# WKUP_CTRL_MMR0_CFG0 register map
Vendor: Texas Instruments
Registers are 32-bit, read-write, reset 0x0 unless marked. A register's access mark holds for its fields unless they carry their own. Offsets are as the file gives them; [hi:lo] are bit positions; {n}, {i} and the like mark numbered series.

## WKUP_CTRL_MMR0_CFG0 (part 8 of 11)
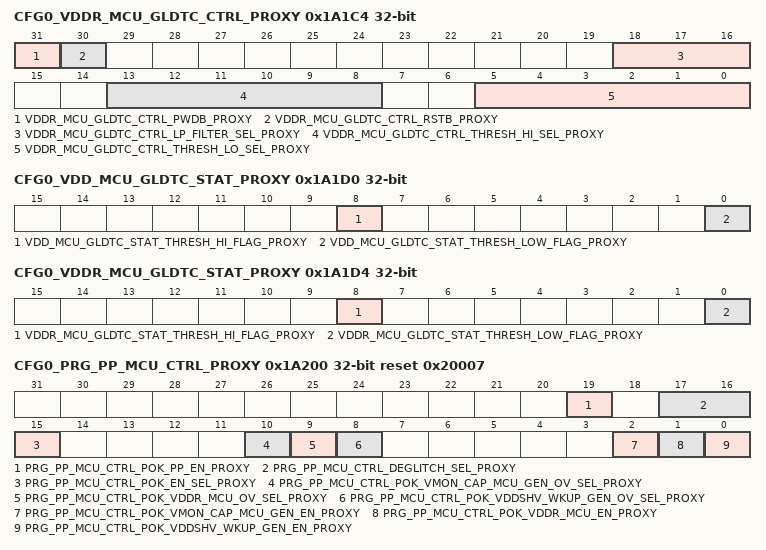
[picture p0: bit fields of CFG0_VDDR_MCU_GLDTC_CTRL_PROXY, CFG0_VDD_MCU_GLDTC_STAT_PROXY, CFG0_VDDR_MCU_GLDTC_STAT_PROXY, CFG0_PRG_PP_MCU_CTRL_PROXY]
0x1A1C4 CFG0_VDDR_MCU_GLDTC_CTRL_PROXY
  [31] VDDR_MCU_GLDTC_CTRL_PWDB_PROXY — Power down - active low. 0 - Disable all functions 1 - Enable glitch detectors
  [30] VDDR_MCU_GLDTC_CTRL_RSTB_PROXY — Reset - active low. To ensure proper operation, rstb must be not be de-asserted for at least 100 ns after power-up (pwdb de-asserted). Additionally, rstb must be toggled low at least 200 ns after any change in threshold or low-pass filter settings to prevent abnormal trigger events. 0 - Reset glitch detector flags 1 - Glitch detection flags are enabled
  [18:16] VDDR_MCU_GLDTC_CTRL_LP_FILTER_SEL_PROXY — Selects the glitch detect low-pass filter bandwidth Field values (others are reserved): 3'b000 - 150 kHz 3'b001 - 125 kHz 3'b010 - 100 kHz 3'b011 - 80 kHz 3'b100 - 60 kHz 3'b101 - 45 kHz 3'b110 - 30 kHz 3'b111 - 15 kHz
  [13:8] VDDR_MCU_GLDTC_CTRL_THRESH_HI_SEL_PROXY — Selects the high voltage glitch threshold as a percentage of the monitored voltage Field values (others are reserved): 6'b000000 - 93.5% of VDD 6'b000001 - 94.0% of VDD 6'b000010 - 94.5% of VDD 6'b000011 - 95.0% of VDD 6'b000100 - 95.5% of VDD 6'b000101 - 96.0% of VDD 6'b000110 - 96.5% of VDD 6'b000111 - 97.0% of VDD 6'b001000 - 97.5% of VDD 6'b001001 - 98.0% of VDD 6'b001010 - 98.5% of VDD 6'b001011 - 99.0% of VDD 6'b001100 - 99.5% of VDD 6'b001101 - 100.0% of VDD 6'b001110 - 100.5% of VDD 6'b001111 - 101.0% of VDD 6'b010000 - 101.5% of VDD 6'b010001 - 102.0% of VDD 6'b010010 - 102.5% of VDD 6'b010011 - 103.0% of VDD 6'b010100 - 103.5% of VDD 6'b010101 - 104.0% of VDD 6'b010110 - 104.5% of VDD 6'b010111 - 105.0% of VDD 6'b011000 - 105.5% of VDD 6'b011001 - 106.0% of VDD 6'b011010 - 106.5% of VDD 6'b011011 - 107.0% of VDD 6'b011100 - 107.5% of VDD 6'b011101 - 108.0% of VDD 6'b011110 - 108.5% of VDD 6'b011111 - 109.0% of VDD 6'b100000 - 109.5% of VDD 6'b100001 - 110.0% of VDD 6'b100010 - 111.0% of VDD 6'b100011 - 112.0% of VDD 6'b100100 - 113.0% of VDD 6'b100101 - 114.0% of VDD 6'b100110 - 115.0% of VDD 6'b100111 - 116.0% of VDD 6'b101000 - 117.0% of VDD 6'b101001 - 118.0% of VDD 6'b101010 - 119.0% of VDD 6'b101011 - 120.0% of VDD 6'b101100 - 121.0% of VDD 6'b101101 - 122.0% of VDD 6'b101110 - 123.0% of VDD 6'b101111 - 124.0% of VDD 6'b110000 - 125.0% of VDD 6'b110001 - 126.0% of VDD 6'b110010 - 127.0% of VDD 6'b110011 - 128.0% of VDD 6'b110100 - 129.0% of VDD 6'b110101 - 130.0% of VDD 6'b110110 - 131.0% of VDD 6'b110111 - 132.0% of VDD 6'b111000 - 133.0% of VDD 6'b111001 - 134.0% of VDD 6'b111010 - 135.0% of VDD 6'b111011 - 136.0% of VDD 6'b111100 - 137.0% of VDD 6'b111101 - 138.0% of VDD 6'b111110 - 139.0% of VDD 6'b111111 - 140.0% of VDD
  [5:0] VDDR_MCU_GLDTC_CTRL_THRESH_LO_SEL_PROXY — Selects the low voltage glitch threshold as a percentage of the monitored voltage Field values (others are reserved): 6'b000000 - 106.5% of VDD 6'b000001 - 106.0% of VDD 6'b000010 - 105.5% of VDD 6'b000011 - 105.0% of VDD 6'b000100 - 104.5% of VDD 6'b000101 - 104.0% of VDD 6'b000110 - 103.5% of VDD 6'b000111 - 103.0% of VDD 6'b001000 - 102.5% of VDD 6'b001001 - 102.0% of VDD 6'b001010 - 101.5% of VDD 6'b001011 - 101.0% of VDD 6'b001100 - 100.5% of VDD 6'b001101 - 100.0% of VDD 6'b001110 - 99.5% of VDD 6'b001111 - 99.0% of VDD 6'b010000 - 98.5% of VDD 6'b010001 - 98.0% of VDD 6'b010010 - 97.5% of VDD 6'b010011 - 97.0% of VDD 6'b010100 - 96.5% of VDD 6'b010101 - 96.0% of VDD 6'b010110 - 95.5% of VDD 6'b010111 - 95.0% of VDD 6'b011000 - 94.5% of VDD 6'b011001 - 94.0% of VDD 6'b011010 - 93.5% of VDD 6'b011011 - 93.0% of VDD 6'b011100 - 92.5% of VDD 6'b011101 - 92.0% of VDD 6'b011110 - 91.5% of VDD 6'b011111 - 91.0% of VDD 6'b100000 - 90.5% of VDD 6'b100001 - 90.0% of VDD 6'b100010 - 89.0% of VDD 6'b100011 - 88.0% of VDD 6'b100100 - 87.0% of VDD 6'b100101 - 86.0% of VDD 6'b100110 - 85.0% of VDD 6'b100111 - 84.0% of VDD 6'b101000 - 83.0% of VDD 6'b101001 - 82.0% of VDD 6'b101010 - 81.0% of VDD 6'b101011 - 80.0% of VDD 6'b101100 - 79.0% of VDD 6'b101101 - 78.0% of VDD 6'b101110 - 77.0% of VDD 6'b101111 - 76.0% of VDD 6'b110000 - 75.0% of VDD 6'b110001 - 74.0% of VDD 6'b110010 - 73.0% of VDD 6'b110011 - 72.0% of VDD 6'b110100 - 71.0% of VDD 6'b110101 - 70.0% of VDD 6'b110110 - 69.0% of VDD 6'b110111 - 68.0% of VDD 6'b111000 - 67.0% of VDD 6'b111001 - 66.0% of VDD 6'b111010 - 65.0% of VDD 6'b111011 - 64.0% of VDD 6'b111100 - 63.0% of VDD 6'b111101 - 62.0% of VDD 6'b111110 - 61.0% of VDD 6'b111111 - 60.0% of VDD
0x1A1D0 CFG0_VDD_MCU_GLDTC_STAT_PROXY ro
  [8] VDD_MCU_GLDTC_STAT_THRESH_HI_FLAG_PROXY — High voltage flag. This flag is cleared by clearing the VDD_MCU_GLDTC_CTRL_rstb bit. 0 - No high voltage detected 1 - Voltage above the high voltage threshold was detected.
  [0] VDD_MCU_GLDTC_STAT_THRESH_LOW_FLAG_PROXY — Low voltage flag. This flag is cleared by clearing the VDD_MCU_GLDTC_CTRL_rstb bit. 0 - No low voltage detected 1 - Voltage below the low voltage threshold was detected.
0x1A1D4 CFG0_VDDR_MCU_GLDTC_STAT_PROXY ro
  [8] VDDR_MCU_GLDTC_STAT_THRESH_HI_FLAG_PROXY — High voltage flag. This flag is cleared by clearing the VDDR_MCU_GLDTC_CTRL_rstb bit. 0 - No high voltage detected 1 - Voltage above the high voltage threshold was detected.
  [0] VDDR_MCU_GLDTC_STAT_THRESH_LOW_FLAG_PROXY — Low voltage flag. This flag is cleared by clearing the VDDR_MCU_GLDTC_CTRL_rstb bit. 0 - No low voltage detected 1 - Voltage below the low voltage threshold was detected.
0x1A200 CFG0_PRG_PP_MCU_CTRL_PROXY reset 0x20007
  [19] PRG_PP_MCU_CTRL_POK_PP_EN_PROXY — POK ping-pong enable. When set, enables automatic switching between undervoltage and overvoltage detection on VDDSHV_WKUP_GENERAL, VDDR_MCU and VMON_CAP_MCU_GENERAL POKs. This bit has no effect if the POK's ov_sel bit = 1. 0 - No pingpong operation. UV/OV operation selected by each POK ov_sel bit 1 - Pingpong operation enabled .
  [17:16] PRG_PP_MCU_CTRL_DEGLITCH_SEL_PROXY — Deglitch period for PRG_PP_MCU POKs Field values (others are reserved): 2'b00 - 5 us 2'b01 - 10 us 2'b10 - 15 us 2'b11 - 20 us
  [15] PRG_PP_MCU_CTRL_POK_EN_SEL_PROXY — Select POK enable source 0 - POK enables come from hardware tie-offs 1 - POK enables come from PRG_PP_MCU_CTRL register
  [10] PRG_PP_MCU_CTRL_POK_VMON_CAP_MCU_GEN_OV_SEL_PROXY — Force VMON_CAP_MCU_GENERAL POK overvoltage detection. If this bit is 0 and pok_pp_en bit is also 0 then only undervoltage detection is enabled. 0 - Undervoltage detection or UV/OV ping-pong operation 1- Overvoltage detection only
  [9] PRG_PP_MCU_CTRL_POK_VDDR_MCU_OV_SEL_PROXY — Force VDDR_MCU POK overvoltage detection. If this bit is 0 and pok_pp_en bit is also 0 then only undervoltage detection is enabled. 0 - Undervoltage detection or UV/OV ping-pong operation 1- Overvoltage detection only
  [8] PRG_PP_MCU_CTRL_POK_VDDSHV_WKUP_GEN_OV_SEL_PROXY — Force VDDSHV_WKUP_GENERAL POK overvoltage detection. If this bit is 0 and pok_pp_en bit is also 0 then only undervoltage detection is enabled. 0 - Undervoltage detection or UV/OV ping-pong operation 1- Overvoltage detection only
  [2] PRG_PP_MCU_CTRL_POK_VMON_CAP_MCU_GEN_EN_PROXY — Enable VMON_CAP_MCU_GENERAL POK detection 0 - POK detection disabled 1 - POK detection enabled
  [1] PRG_PP_MCU_CTRL_POK_VDDR_MCU_EN_PROXY — Enable VDDR_MCU POK detection 0 - POK detection disabled 1 - POK detection enabled
  [0] PRG_PP_MCU_CTRL_POK_VDDSHV_WKUP_GEN_EN_PROXY — Enable VDDSHV_WKUP_GENERAL POK detection 0 - POK detection disabled 1 - POK detection enabled
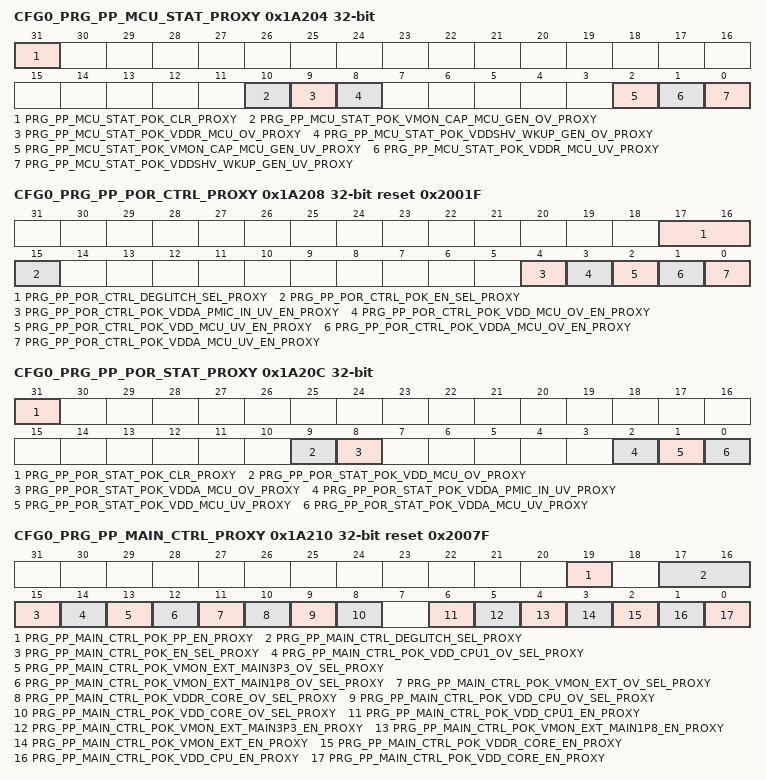
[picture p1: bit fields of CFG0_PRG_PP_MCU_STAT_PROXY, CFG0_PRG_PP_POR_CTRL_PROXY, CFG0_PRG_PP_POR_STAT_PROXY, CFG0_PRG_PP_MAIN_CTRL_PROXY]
0x1A204 CFG0_PRG_PP_MCU_STAT_PROXY access per field
  [31] PRG_PP_MCU_STAT_POK_CLR_PROXY rw — When set, resets pgood sticky bits for VDDSHV_WKUP_GENERAL, VDDR_MCU, and VMON_CAP_MCU_GENERAL voltage POK detection.
  [10] PRG_PP_MCU_STAT_POK_VMON_CAP_MCU_GEN_OV_PROXY ro — VMON_CAP_MCU_GENERAL overvoltage POK 0 - Voltage good 1 - Voltage above threshold
  [9] PRG_PP_MCU_STAT_POK_VDDR_MCU_OV_PROXY ro — VDDR_MCU overvoltage POK 0 - Voltage good 1 - Voltage above threshold
  [8] PRG_PP_MCU_STAT_POK_VDDSHV_WKUP_GEN_OV_PROXY ro — VDDSHV_WKUP_GENERAL overvoltage POK 0 - Voltage good 1 - Voltage above threshold
  [2] PRG_PP_MCU_STAT_POK_VMON_CAP_MCU_GEN_UV_PROXY ro — VMON_CAP_MCU_GENERAL undervoltage POK 0 - Voltage good 1 - Voltage below threshold
  [1] PRG_PP_MCU_STAT_POK_VDDR_MCU_UV_PROXY ro — VDDR_MCU undervoltage POK 0 - Voltage good 1 - Voltage below threshold
  [0] PRG_PP_MCU_STAT_POK_VDDSHV_WKUP_GEN_UV_PROXY ro — VDDSHV_WKUP_GENERAL undervoltage POK 0 - Voltage good 1 - Voltage below threshold
0x1A208 CFG0_PRG_PP_POR_CTRL_PROXY reset 0x2001F
  [17:16] PRG_PP_POR_CTRL_DEGLITCH_SEL_PROXY — Deglitch period for PRG_PP_POR POKs Field values (others are reserved): 2'b00 - 5 us 2'b01 - 10 us 2'b10 - 15 us 2'b11 - 20 us
  [15] PRG_PP_POR_CTRL_POK_EN_SEL_PROXY — Select POK enable source 0 - POK enables come from hardware tie-offs 1 - POK enables come from PRG_PP_POR_CTRL register
  [4] PRG_PP_POR_CTRL_POK_VDDA_PMIC_IN_UV_EN_PROXY — Enable VDDA_PMIC_IN undervoltage POK detection 0 - POK detection disabled 1 - POK detection enabled
  [3] PRG_PP_POR_CTRL_POK_VDD_MCU_OV_EN_PROXY — Enable VDD_MCU overvoltage POK detection 0 - POK detection disabled 1 - POK detection enabled
  [2] PRG_PP_POR_CTRL_POK_VDD_MCU_UV_EN_PROXY — Enable VDD_MCU undervoltage POK detection 0 - POK detection disabled 1 - POK detection enabled
  [1] PRG_PP_POR_CTRL_POK_VDDA_MCU_OV_EN_PROXY — Enable 1.8V VDDA_MCU overvoltage POK detection 0 - POK detection disabled 1 - POK detection enabled
  [0] PRG_PP_POR_CTRL_POK_VDDA_MCU_UV_EN_PROXY — Enable 1.8V VDDA_MCU undervoltage POK detection 0 - POK detection disabled 1 - POK detection enabled
0x1A20C CFG0_PRG_PP_POR_STAT_PROXY access per field
  [31] PRG_PP_POR_STAT_POK_CLR_PROXY rw — When set, resets pgood sticky bits for VDDA_MCU, VDD_MCU, and VDDA_PMIC_IN voltage POK detection.
  [9] PRG_PP_POR_STAT_POK_VDD_MCU_OV_PROXY ro — VDD_MCU overvoltage POK detection 0 - Voltage good 1 - Voltage above threshold
  [8] PRG_PP_POR_STAT_POK_VDDA_MCU_OV_PROXY ro — 1.8V VDDA_MCU overvoltage POK detection 0 - Voltage good 1 - Voltage above threshold
  [2] PRG_PP_POR_STAT_POK_VDDA_PMIC_IN_UV_PROXY ro — VDDA_PMIC_IN undervoltage POK detection 0 - Voltage good 1 - Voltage below threshold
  [1] PRG_PP_POR_STAT_POK_VDD_MCU_UV_PROXY ro — VDD_MCU undervoltage POK detection 0 - Voltage good 1 - Voltage below threshold
  [0] PRG_PP_POR_STAT_POK_VDDA_MCU_UV_PROXY ro — 1.8V VDDA_MCU undervoltage POK detection 0 - Voltage good 1 - Voltage below threshold
0x1A210 CFG0_PRG_PP_MAIN_CTRL_PROXY reset 0x2007F
  [19] PRG_PP_MAIN_CTRL_POK_PP_EN_PROXY — POK ping-pong enable. When set, enables automatic switching between undervoltage and overvoltage detection on VDD_CORE, VDD_CPU, VDDR_CORE, VMON_EXT, VMON_EXT_MAIN1P8 and VMON_EXT_MAIN3P3. This bit has no effect if the POK's ov_sel bit = 1. 0 - No pingpong operation. UV/OV operation selected by each POK ov_sel bit 1 - Pingpong operation enabled .
  [17:16] PRG_PP_MAIN_CTRL_DEGLITCH_SEL_PROXY — Deglitch period for PRG_PP_MAIN POKs Field values (others are reserved): 2'b00 - 5 us 2'b01 - 10 us 2'b10 - 15 us 2'b11 - 20 us
  [15] PRG_PP_MAIN_CTRL_POK_EN_SEL_PROXY — Select POK enable source 0 - POK enables come from hardware tie-offs 1 - POK enables come from PRG_PP_MAIN_CTRL register
  [14] PRG_PP_MAIN_CTRL_POK_VDD_CPU1_OV_SEL_PROXY — Force VDD_CPU1 POK overvoltage detection. If this bit is 0 and pok_pp_en bit is also 0 then only undervoltage detection is enabled. 0 - Undervoltage detection or UV/OV ping-pong operation 1- Overvoltage detection only
  [13] PRG_PP_MAIN_CTRL_POK_VMON_EXT_MAIN3P3_OV_SEL_PROXY — Force VMON_EXT_MAIN 3.3V POK overvoltage detection. If this bit is 0 and pok_pp_en bit is also 0 then only undervoltage detection is enabled. 0 - Undervoltage detection or UV/OV ping-pong operation 1- Overvoltage detection only
  [12] PRG_PP_MAIN_CTRL_POK_VMON_EXT_MAIN1P8_OV_SEL_PROXY — Force VMON_EXT_MAIN 1.8V POK overvoltage detection. If this bit is 0 and pok_pp_en bit is also 0 then only undervoltage detection is enabled. 0 - Undervoltage detection or UV/OV ping-pong operation 1- Overvoltage detection only
  [11] PRG_PP_MAIN_CTRL_POK_VMON_EXT_OV_SEL_PROXY — Force VMON_EXT POK overvoltage detection. If this bit is 0 and pok_pp_en bit is also 0 then only undervoltage detection is enabled. 0 - Undervoltage detection or UV/OV ping-pong operation 1- Overvoltage detection only
  [10] PRG_PP_MAIN_CTRL_POK_VDDR_CORE_OV_SEL_PROXY — Force VDDR_CORE POK overvoltage detection. If this bit is 0 and pok_pp_en bit is also 0 then only undervoltage detection is enabled. 0 - Undervoltage detection or UV/OV ping-pong operation 1- Overvoltage detection only
  [9] PRG_PP_MAIN_CTRL_POK_VDD_CPU_OV_SEL_PROXY — Force VDD_CPU POK overvoltage detection. If this bit is 0 and pok_pp_en bit is also 0 then only undervoltage detection is enabled. 0 - Undervoltage detection or UV/OV ping-pong operation 1- Overvoltage detection only
  [8] PRG_PP_MAIN_CTRL_POK_VDD_CORE_OV_SEL_PROXY — Force VDD_CORE POK overvoltage detection. If this bit is 0 and pok_pp_en bit is also 0 then only undervoltage detection is enabled. 0 - Undervoltage detection or UV/OV ping-pong operation 1- Overvoltage detection only
  [6] PRG_PP_MAIN_CTRL_POK_VDD_CPU1_EN_PROXY — Enable VDD_CPU1 POK detection 0 - POK detection disabled 1 - POK detection enabled
  [5] PRG_PP_MAIN_CTRL_POK_VMON_EXT_MAIN3P3_EN_PROXY — Enable VMON_EXT_MAIN 3.3V POK detection 0 - POK detection disabled 1 - POK detection enabled
  [4] PRG_PP_MAIN_CTRL_POK_VMON_EXT_MAIN1P8_EN_PROXY — Enable VMON_EXT_MAIN 1.8V POK detection 0 - POK detection disabled 1 - POK detection enabled
  [3] PRG_PP_MAIN_CTRL_POK_VMON_EXT_EN_PROXY — Enable VMON_EXT POK detection 0 - POK detection disabled 1 - POK detection enabled
  [2] PRG_PP_MAIN_CTRL_POK_VDDR_CORE_EN_PROXY — Enable VDDR_CORE POK detection 0 - POK detection disabled 1 - POK detection enabled
  [1] PRG_PP_MAIN_CTRL_POK_VDD_CPU_EN_PROXY — Enable VDD_CPU POK detection 0 - POK detection disabled 1 - POK detection enabled
  [0] PRG_PP_MAIN_CTRL_POK_VDD_CORE_EN_PROXY — Enable VDD_CORE POK detection 0 - POK detection disabled 1 - POK detection enabled
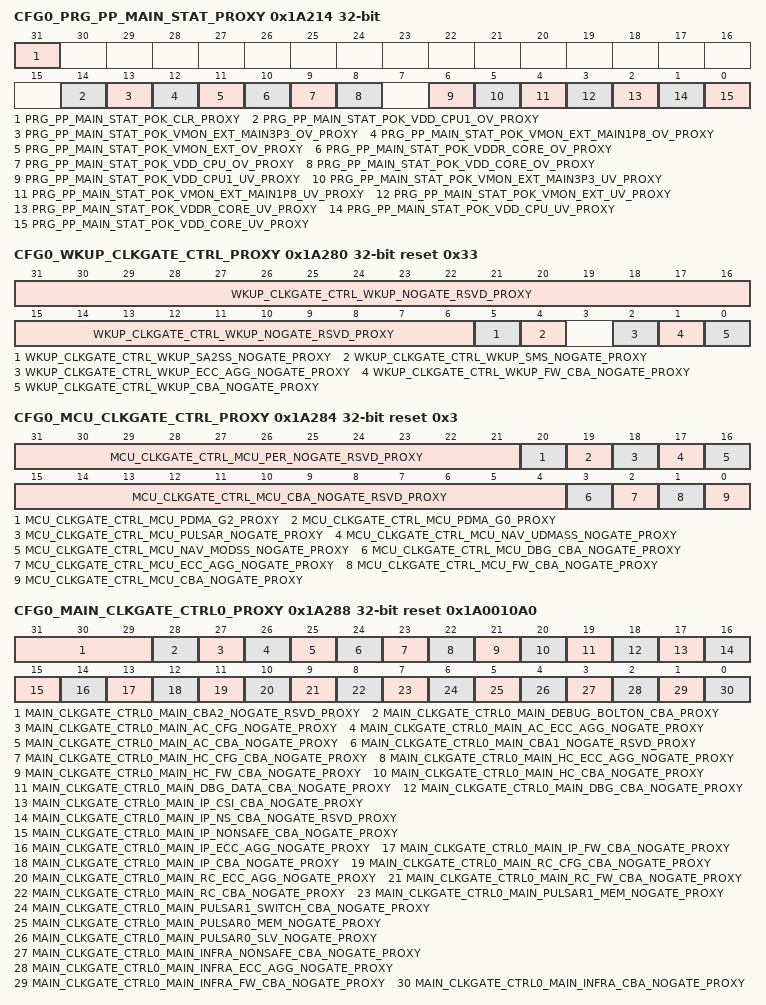
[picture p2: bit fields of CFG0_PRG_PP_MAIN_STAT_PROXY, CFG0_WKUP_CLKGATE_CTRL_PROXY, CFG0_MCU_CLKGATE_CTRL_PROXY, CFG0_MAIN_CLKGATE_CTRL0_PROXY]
0x1A214 CFG0_PRG_PP_MAIN_STAT_PROXY access per field
  [31] PRG_PP_MAIN_STAT_POK_CLR_PROXY rw — When set, resets pgood sticky bits for VDD_CORE, VDD_CPU, VDDR_CORE, VMON_EXT, VMON_EXT_MAIN1P8, and VMON_EXT_MAIN3P3 voltage POK detection.
  [14] PRG_PP_MAIN_STAT_POK_VDD_CPU1_OV_PROXY ro — VDD_CPU1 overvoltage POK 0 - Voltage good 1 - Voltage above threshold
  [13] PRG_PP_MAIN_STAT_POK_VMON_EXT_MAIN3P3_OV_PROXY ro — VMON_EXT_MAIN 3.3V overvoltage POK 0 - Voltage good 1 - Voltage above threshold
  [12] PRG_PP_MAIN_STAT_POK_VMON_EXT_MAIN1P8_OV_PROXY ro — VMON_EXT_MAIN 1.8V overvoltage POK 0 - Voltage good 1 - Voltage above threshold
  [11] PRG_PP_MAIN_STAT_POK_VMON_EXT_OV_PROXY ro — VMON_EXT overvoltage POK 0 - Voltage good 1 - Voltage above threshold
  [10] PRG_PP_MAIN_STAT_POK_VDDR_CORE_OV_PROXY ro — VDDR_CORE overvoltage POK 0 - Voltage good 1 - Voltage above threshold
  [9] PRG_PP_MAIN_STAT_POK_VDD_CPU_OV_PROXY ro — VDD_CPU overvoltage POK 0 - Voltage good 1 - Voltage above threshold
  [8] PRG_PP_MAIN_STAT_POK_VDD_CORE_OV_PROXY ro — VDD_CORE overvoltage POK 0 - Voltage good 1 - Voltage above threshold
  [6] PRG_PP_MAIN_STAT_POK_VDD_CPU1_UV_PROXY ro — VDD_CPU1 undervoltage POK 0 - Voltage good 1 - Voltage below threshold
  [5] PRG_PP_MAIN_STAT_POK_VMON_EXT_MAIN3P3_UV_PROXY ro — VMON_EXT_MAIN 3.3V undervoltage POK 0 - Voltage good 1 - Voltage below threshold
  [4] PRG_PP_MAIN_STAT_POK_VMON_EXT_MAIN1P8_UV_PROXY ro — VMON_EXT_MAIN 1.8V undervoltage POK 0 - Voltage good 1 - Voltage below threshold
  [3] PRG_PP_MAIN_STAT_POK_VMON_EXT_UV_PROXY ro — VMON_EXT undervoltage POK 0 - Voltage good 1 - Voltage below threshold
  [2] PRG_PP_MAIN_STAT_POK_VDDR_CORE_UV_PROXY ro — VDDR_CORE undervoltage POK 0 - Voltage good 1 - Voltage below threshold
  [1] PRG_PP_MAIN_STAT_POK_VDD_CPU_UV_PROXY ro — VDD_CPU undervoltage POK 0 - Voltage good 1 - Voltage below threshold
  [0] PRG_PP_MAIN_STAT_POK_VDD_CORE_UV_PROXY ro — VDD_CORE undervoltage POK 0 - Voltage good 1 - Voltage below threshold
0x1A280 CFG0_WKUP_CLKGATE_CTRL_PROXY reset 0x33
  [31:6] WKUP_CLKGATE_CTRL_WKUP_NOGATE_RSVD_PROXY — WKUP reserved clock gate disable. These bits should remain unchanged (written only with their default value) to maintain compatibility with future devices. 0 - Clocks are gated on idle for power savings 1 - Clocks are not gated on idle, power saving disabled
  [5] WKUP_CLKGATE_CTRL_WKUP_SA2SS_NOGATE_PROXY — WKUP SA2SS clock gate disable 0 - Clocks are gated on idle for power savings 1 - Clocks are not gated on idle, power saving disabled
  [4] WKUP_CLKGATE_CTRL_WKUP_SMS_NOGATE_PROXY — WKUP SMS clock gate disable 0 - Clocks are gated on idle for power savings 1 - Clocks are not gated on idle, power saving disabled
  [2] WKUP_CLKGATE_CTRL_WKUP_ECC_AGG_NOGATE_PROXY — WKUP ECC Aggregator clock gate disable 0 - Clocks are gated on idle for power savings 1 - Clocks are not gated on idle, power saving disabled
  [1] WKUP_CLKGATE_CTRL_WKUP_FW_CBA_NOGATE_PROXY — WKUP domain Firewall bus (wkup_fw_cbass) clock gate disable 0 - Clocks are gated on idle for power savings 1 - Clocks are not gated on idle, power saving disabled
  [0] WKUP_CLKGATE_CTRL_WKUP_CBA_NOGATE_PROXY — WKUP domain Data bus (wkup_cbass) clock gate disable 0 - Clocks are gated on idle for power savings 1 - Clocks are not gated on idle, power saving disabled
0x1A284 CFG0_MCU_CLKGATE_CTRL_PROXY reset 0x3
  [31:21] MCU_CLKGATE_CTRL_MCU_PER_NOGATE_RSVD_PROXY — MCU reserved clock gate disable. These bits should remain unchanged (written only with their default value) to maintain compatibility with future devices. 0 - Clocks are gated on idle for power savings 1 - Clocks are not gated on idle, power saving disabled
  [20] MCU_CLKGATE_CTRL_MCU_PDMA_G2_PROXY — MCU domain MCAN1/USART0 PDMA clock gate disable. 0 - Clocks are gated on idle for power savings 1 - Clocks are not gated on idle, power saving disabled
  [19] MCU_CLKGATE_CTRL_MCU_PDMA_G0_PROXY — MCU domain MCAN0/SPI0 PDMA clock gate disable. 0 - Clocks are gated on idle for power savings 1 - Clocks are not gated on idle, power saving disabled
  [18] MCU_CLKGATE_CTRL_MCU_PULSAR_NOGATE_PROXY — MCU domain Pulsar clock gate disable. 0 - Clocks are gated on idle for power savings 1 - Clocks are not gated on idle, power saving disabled
  [17] MCU_CLKGATE_CTRL_MCU_NAV_UDMASS_NOGATE_PROXY — MCU NavSS UDMA interface clock gate disable. 0 - Clocks are gated on idle for power savings 1 - Clocks are not gated on idle, power saving disabled
  [16] MCU_CLKGATE_CTRL_MCU_NAV_MODSS_NOGATE_PROXY — MCU NavSS MODSS interface clock gate disable. 0 - Clocks are gated on idle for power savings 1 - Clocks are not gated on idle, power saving disabled
  [15:4] MCU_CLKGATE_CTRL_MCU_CBA_NOGATE_RSVD_PROXY — MCU reserved clock gate disable. These bits should remain unchanged (written only with their default value) to maintain compatibility with future devices. 0 - Clocks are gated on idle for power savings 1 - Clocks are not gated on idle, power saving disabled
  [3] MCU_CLKGATE_CTRL_MCU_DBG_CBA_NOGATE_PROXY — MCU domain Debug bus (mcu_dbg_cbass) clock gate disable. 0 - Clocks are gated on idle for power savings 1 - Clocks are not gated on idle, power saving disabled
  [2] MCU_CLKGATE_CTRL_MCU_ECC_AGG_NOGATE_PROXY — MCU ECC Aggregator clock gate disable 0 - Clocks are gated on idle for power savings 1 - Clocks are not gated on idle, power saving disabled
  [1] MCU_CLKGATE_CTRL_MCU_FW_CBA_NOGATE_PROXY — MCU domain Firewall bus (mcu_fw_cbass) clock gate disable. 0 - Clocks are gated on idle for power savings 1 - Clocks are not gated on idle, power saving disabled
  [0] MCU_CLKGATE_CTRL_MCU_CBA_NOGATE_PROXY — MCU domain Data bus (mcu_cbass) clock gate disable. 0 - Clocks are gated on idle for power savings 1 - Clocks are not gated on idle, power saving disabled
0x1A288 CFG0_MAIN_CLKGATE_CTRL0_PROXY reset 0x1A0010A0
  [31:29] MAIN_CLKGATE_CTRL0_MAIN_CBA2_NOGATE_RSVD_PROXY — MAIN CBA reserved clock gate disable. These bits should remain unchanged (written only with their default value) to maintain compatibility with future devices. 0 - Clocks are gated on idle for power savings 1 - Clocks are not gated on idle, power saving disabled
  [28] MAIN_CLKGATE_CTRL0_MAIN_DEBUG_BOLTON_CBA_PROXY — MAIN domain debug bolton bus (debug_bolton_cbass) clock gate disable. 0 - Clocks are gated on idle for power savings 1 - Clocks are not gated on idle, power saving disabled
  [27] MAIN_CLKGATE_CTRL0_MAIN_AC_CFG_NOGATE_PROXY — MAIN domain AC Configuration bus (ac_cfg_fw_cbass) clock gate disable. 0 - Clocks are gated on idle for power savings 1 - Clocks are not gated on idle, power saving disabled
  [26] MAIN_CLKGATE_CTRL0_MAIN_AC_ECC_AGG_NOGATE_PROXY — MAIN domain AC ECC aggregator bus (ac_pipe_ecc_aggr) clock gate disable. 0 - Clocks are gated on idle for power savings 1 - Clocks are not gated on idle, power saving disabled
  [25] MAIN_CLKGATE_CTRL0_MAIN_AC_CBA_NOGATE_PROXY — MAIN domain AC Firewall bus (ac_pipe_cbass_main_fw_cbass_0) clock gate disable. 0 - Clocks are gated on idle for power savings 1 - Clocks are not gated on idle, power saving disabled
  [24] MAIN_CLKGATE_CTRL0_MAIN_CBA1_NOGATE_RSVD_PROXY — MAIN CBA reserved clock gate disable. These bits should remain unchanged (written only with their default value) to maintain compatibility with future devices. 0 - Clocks are gated on idle for power savings 1 - Clocks are not gated on idle, power saving disabled
  [23] MAIN_CLKGATE_CTRL0_MAIN_HC_CFG_CBA_NOGATE_PROXY — MAIN domain HC Configuration bus (hc_cfg_cbass_0) clock gate disable. 0 - Clocks are gated on idle for power savings 1 - Clocks are not gated on idle, power saving disabled
  [22] MAIN_CLKGATE_CTRL0_MAIN_HC_ECC_AGG_NOGATE_PROXY — MAIN domain HC ECC aggregator (nogate) clock gate disable. 0 - Clocks are gated on idle for power savings 1 - Clocks are not gated on idle, power saving disabled
  [21] MAIN_CLKGATE_CTRL0_MAIN_HC_FW_CBA_NOGATE_PROXY — MAIN domain HC Firewall bus (main_hc2_fw_cbass_0) clock gate disable. 0 - Clocks are gated on idle for power savings 1 - Clocks are not gated on idle, power saving disabled
  [20] MAIN_CLKGATE_CTRL0_MAIN_HC_CBA_NOGATE_PROXY — MAIN domain HC Data bus (hc2_cbass_0) clock gate disable. 0 - Clocks are gated on idle for power savings 1 - Clocks are not gated on idle, power saving disabled
  [19] MAIN_CLKGATE_CTRL0_MAIN_DBG_DATA_CBA_NOGATE_PROXY — MAIN domain Debug Data bus (debug_cbass) clock gate disable. 0 - Clocks are gated on idle for power savings 1 - Clocks are not gated on idle, power saving disabled
  [18] MAIN_CLKGATE_CTRL0_MAIN_DBG_CBA_NOGATE_PROXY — MAIN domain Debug bus (debug_cbass_wrap_main_0) clock gate disable. 0 - Clocks are gated on idle for power savings 1 - Clocks are not gated on idle, power saving disabled
  [17] MAIN_CLKGATE_CTRL0_MAIN_IP_CSI_CBA_NOGATE_PROXY — MAIN domain CSI bus (csi_cbass_0) clock gate disable. 0 - Clocks are gated on idle for power savings 1 - Clocks are not gated on idle, power saving disabled
  [16] MAIN_CLKGATE_CTRL0_MAIN_IP_NS_CBA_NOGATE_RSVD_PROXY — MAIN nonsafety CBA reserved clock gate disable. These bits should remain unchanged (written only with their default value) to maintain compatibility with future devices. 0 - Clocks are gated on idle for power savings 1 - Clocks are not gated on idle, power saving disabled
  [15] MAIN_CLKGATE_CTRL0_MAIN_IP_NONSAFE_CBA_NOGATE_PROXY — MAIN domain Interface Peripheral nonsafety IP bus (ipphy_cbass_0) clock gate disable. 0 - Clocks are gated on idle for power savings 1 - Clocks are not gated on idle, power saving disabled
  [14] MAIN_CLKGATE_CTRL0_MAIN_IP_ECC_AGG_NOGATE_PROXY — MAIN domain Interface Peripheral ECC aggregator (main_spi0_g0_main_0_ecc_aggr_main_0) clock gate disable. 0 - Clocks are gated on idle for power savings 1 - Clocks are not gated on idle, power saving disabled
  [13] MAIN_CLKGATE_CTRL0_MAIN_IP_FW_CBA_NOGATE_PROXY — MAIN domain Interface Peripheral Firewall bus (ipphy_cbass_main_fw_cbass) clock gate disable. 0 - Clocks are gated on idle for power savings 1 - Clocks are not gated on idle, power saving disabled
  [12] MAIN_CLKGATE_CTRL0_MAIN_IP_CBA_NOGATE_PROXY — MAIN domain Interface Peripheral bus (ipphy_safe_cbass_0) clock gate disable. 0 - Clocks are gated on idle for power savings 1 - Clocks are not gated on idle, power saving disabled
  [11] MAIN_CLKGATE_CTRL0_MAIN_RC_CFG_CBA_NOGATE_PROXY — MAIN domain RC Configuration bus (rc_cfg_cbass_0) clock gate disable. 0 - Clocks are gated on idle for power savings 1 - Clocks are not gated on idle, power saving disabled
  [10] MAIN_CLKGATE_CTRL0_MAIN_RC_ECC_AGG_NOGATE_PROXY — MAIN domain RC ECC aggregator (main_rc_ecc_aggr_main_0) clock gate disable. 0 - Clocks are gated on idle for power savings 1 - Clocks are not gated on idle, power saving disabled
  [9] MAIN_CLKGATE_CTRL0_MAIN_RC_FW_CBA_NOGATE_PROXY — MAIN domain RC Firewall bus (rc_cbass_main_fw_cbass) clock gate disable. 0 - Clocks are gated on idle for power savings 1 - Clocks are not gated on idle, power saving disabled
  [8] MAIN_CLKGATE_CTRL0_MAIN_RC_CBA_NOGATE_PROXY — MAIN domain RC Data bus (rc_cbass_0) clock gate disable. 0 - Clocks are gated on idle for power savings 1 - Clocks are not gated on idle, power saving disabled
  [7] MAIN_CLKGATE_CTRL0_MAIN_PULSAR1_MEM_NOGATE_PROXY — MAIN domain Pulsar 1 memory bus (pulsar1_mem_cbass) clock gate disable. 0 - Clocks are gated on idle for power savings 1 - Clocks are not gated on idle, power saving disabled
  [6] MAIN_CLKGATE_CTRL0_MAIN_PULSAR1_SWITCH_CBA_NOGATE_PROXY — MAIN domain Pulsar 1 peripheral switch bus (pulsar1_periph_switch_cbass) clock gate disable. 0 - Clocks are gated on idle for power savings 1 - Clocks are not gated on idle, power saving disabled
  [5] MAIN_CLKGATE_CTRL0_MAIN_PULSAR0_MEM_NOGATE_PROXY — MAIN domain Pulsar 0 memory bus (pulsar0_mem_cbass) clock gate disable. 0 - Clocks are gated on idle for power savings 1 - Clocks are not gated on idle, power saving disabled
  [4] MAIN_CLKGATE_CTRL0_MAIN_PULSAR0_SLV_NOGATE_PROXY — MAIN domain Pulsar slave bus (pulsar0_slv_cbass) clock gate disable. 0 - Clocks are gated on idle for power savings 1 - Clocks are not gated on idle, power saving disabled
  [3] MAIN_CLKGATE_CTRL0_MAIN_INFRA_NONSAFE_CBA_NOGATE_PROXY — MAIN domain Infrastructure non-safety IP bus (main_infra_non_safe_cbass) clock gate disable. 0 - Clocks are gated on idle for power savings 1 - Clocks are not gated on idle, power saving disabled
  [2] MAIN_CLKGATE_CTRL0_MAIN_INFRA_ECC_AGG_NOGATE_PROXY — MAIN domain Infrastructure ECC aggregator (main_infra_ecc_aggr) clock gate disable. 0 - Clocks are gated on idle for power savings 1 - Clocks are not gated on idle, power saving disabled
  [1] MAIN_CLKGATE_CTRL0_MAIN_INFRA_FW_CBA_NOGATE_PROXY — MAIN domain Infrastructure Firewall bus (main_infra_fw_cbass) clock gate disable. 0 - Clocks are gated on idle for power savings 1 - Clocks are not gated on idle, power saving disabled
  [0] MAIN_CLKGATE_CTRL0_MAIN_INFRA_CBA_NOGATE_PROXY — MAIN domain Infrastructure bus (main_infra_cbass) clock gate disable. 0 - Clocks are gated on idle for power savings 1 - Clocks are not gated on idle, power saving disabled
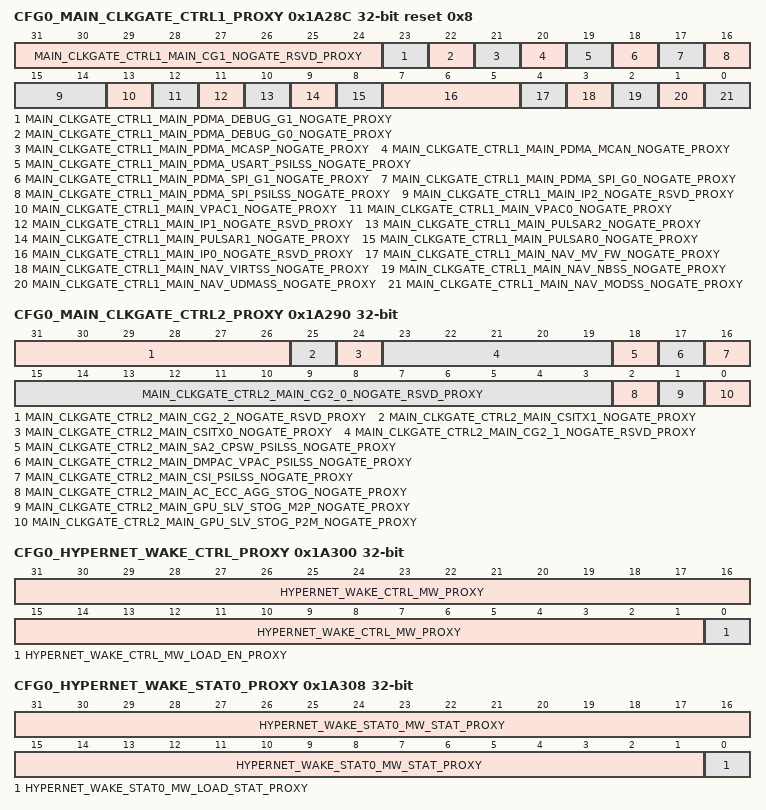
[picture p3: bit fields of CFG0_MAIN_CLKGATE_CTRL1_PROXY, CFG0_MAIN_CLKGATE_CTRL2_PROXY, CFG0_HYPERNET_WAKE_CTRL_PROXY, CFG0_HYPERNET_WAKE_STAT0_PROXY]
0x1A28C CFG0_MAIN_CLKGATE_CTRL1_PROXY reset 0x8
  [31:24] MAIN_CLKGATE_CTRL1_MAIN_CG1_NOGATE_RSVD_PROXY — MAIN PDMA clock gate disable. These bits should remain unchanged (written only with their default value) to maintain compatibility with future devices. 0 - Clocks are gated on idle for power savings 1 - Clocks are not gated on idle, power saving disabled
  [23] MAIN_CLKGATE_CTRL1_MAIN_PDMA_DEBUG_G1_NOGATE_PROXY — MAIN domain PDMA Debug_G1 clock gate disable. 0 - Clocks are gated on idle for power savings 1 - Clocks are not gated on idle, power saving disabled
  [22] MAIN_CLKGATE_CTRL1_MAIN_PDMA_DEBUG_G0_NOGATE_PROXY — MAIN domain PDMA Debug_G0 clock gate disable. 0 - Clocks are gated on idle for power savings 1 - Clocks are not gated on idle, power saving disabled
  [21] MAIN_CLKGATE_CTRL1_MAIN_PDMA_MCASP_NOGATE_PROXY — MAIN domain PDMA MCASP clock gate disable. 0 - Clocks are gated on idle for power savings 1 - Clocks are not gated on idle, power saving disabled
  [20] MAIN_CLKGATE_CTRL1_MAIN_PDMA_MCAN_NOGATE_PROXY — MAIN domain PDMA MCAN clock gate disable. 0 - Clocks are gated on idle for power savings 1 - Clocks are not gated on idle, power saving disabled
  [19] MAIN_CLKGATE_CTRL1_MAIN_PDMA_USART_PSILSS_NOGATE_PROXY — MAIN domain PDMA USART PSILSS clock gate disable. 0 - Clocks are gated on idle for power savings 1 - Clocks are not gated on idle, power saving disabled
  [18] MAIN_CLKGATE_CTRL1_MAIN_PDMA_SPI_G1_NOGATE_PROXY — MAIN domain PDMA SPI_G1 clock gate disable. 0 - Clocks are gated on idle for power savings 1 - Clocks are not gated on idle, power saving disabled
  [17] MAIN_CLKGATE_CTRL1_MAIN_PDMA_SPI_G0_NOGATE_PROXY — MAIN domain PDMA SPI_G0 clock gate disable. 0 - Clocks are gated on idle for power savings 1 - Clocks are not gated on idle, power saving disabled
  [16] MAIN_CLKGATE_CTRL1_MAIN_PDMA_SPI_PSILSS_NOGATE_PROXY — MAIN domain PDMA SPI PSILSS clock gate disable. 0 - Clocks are gated on idle for power savings 1 - Clocks are not gated on idle, power saving disabled
  [15:14] MAIN_CLKGATE_CTRL1_MAIN_IP2_NOGATE_RSVD_PROXY — MAIN IP reserved clock gate disable. These bits should remain unchanged (written only with their default value) to maintain compatibility with future devices. 0 - Clocks are gated on idle for power savings 1 - Clocks are not gated on idle, power saving disabled
  [13] MAIN_CLKGATE_CTRL1_MAIN_VPAC1_NOGATE_PROXY — MAIN domain VPAC 1 clock gate disable. 0 - Clocks are gated on idle for power savings 1 - Clocks are not gated on idle, power saving disabled
  [12] MAIN_CLKGATE_CTRL1_MAIN_VPAC0_NOGATE_PROXY — MAIN domain VPAC 0 clock gate disable. 0 - Clocks are gated on idle for power savings 1 - Clocks are not gated on idle, power saving disabled
  [11] MAIN_CLKGATE_CTRL1_MAIN_IP1_NOGATE_RSVD_PROXY — MAIN IP reserved clock gate disable. These bits should remain unchanged (written only with their default value) to maintain compatibility with future devices. 0 - Clocks are gated on idle for power savings 1 - Clocks are not gated on idle, power saving disabled
  [10] MAIN_CLKGATE_CTRL1_MAIN_PULSAR2_NOGATE_PROXY — MAIN domain Pulsar 2 clock gate disable. 0 - Clocks are gated on idle for power savings 1 - Clocks are not gated on idle, power saving disabled
  [9] MAIN_CLKGATE_CTRL1_MAIN_PULSAR1_NOGATE_PROXY — MAIN domain Pulsar 1 clock gate disable. 0 - Clocks are gated on idle for power savings 1 - Clocks are not gated on idle, power saving disabled
  [8] MAIN_CLKGATE_CTRL1_MAIN_PULSAR0_NOGATE_PROXY — MAIN domain Pulsar 0 clock gate disable. 0 - Clocks are gated on idle for power savings 1 - Clocks are not gated on idle, power saving disabled
  [7:5] MAIN_CLKGATE_CTRL1_MAIN_IP0_NOGATE_RSVD_PROXY — MAIN IP reserved clock gate disable. These bits should remain unchanged (written only with their default value) to maintain compatibility with future devices. 0 - Clocks are gated on idle for power savings 1 - Clocks are not gated on idle, power saving disabled
  [4] MAIN_CLKGATE_CTRL1_MAIN_NAV_MV_FW_NOGATE_PROXY — MAIN NavSS Mod/Virt Firewall interface clock gate disable. 0 - Clocks are gated on idle for power savings 1 - Clocks are not gated on idle, power saving disabled
  [3] MAIN_CLKGATE_CTRL1_MAIN_NAV_VIRTSS_NOGATE_PROXY — MAIN NavSS VIRTSS interface clock gate disable. 0 - Clocks are gated on idle for power savings 1 - Clocks are not gated on idle, power saving disabled
  [2] MAIN_CLKGATE_CTRL1_MAIN_NAV_NBSS_NOGATE_PROXY — MAIN NavSS NB interface clock gate disable. 0 - Clocks are gated on idle for power savings 1 - Clocks are not gated on idle, power saving disabled
  [1] MAIN_CLKGATE_CTRL1_MAIN_NAV_UDMASS_NOGATE_PROXY — Main NavSS UDMA interface clock gate disable. 0 - Clocks are gated on idle for power savings 1 - Clocks are not gated on idle, power saving disabled
  [0] MAIN_CLKGATE_CTRL1_MAIN_NAV_MODSS_NOGATE_PROXY — MAIN NavSS MODSS interface clock gate disable. 0 - Clocks are gated on idle for power savings 1 - Clocks are not gated on idle, power saving disabled
0x1A290 CFG0_MAIN_CLKGATE_CTRL2_PROXY
  [31:26] MAIN_CLKGATE_CTRL2_MAIN_CG2_2_NOGATE_RSVD_PROXY — MAIN domain spare clock gate disable. These bits should remain unchanged (written only with their default value) to maintain compatibility with future devices. 0 - Clocks are gated on idle for power savings 1 - Clocks are not gated on idle, power saving disabled
  [25] MAIN_CLKGATE_CTRL2_MAIN_CSITX1_NOGATE_PROXY — MAIN domain CSI_TX1 clock gate disable. 0 - Clocks are gated on idle for power savings 1 - Clocks are not gated on idle, power saving disabled
  [24] MAIN_CLKGATE_CTRL2_MAIN_CSITX0_NOGATE_PROXY — MAIN domain CSI_TX0 clock gate disable. 0 - Clocks are gated on idle for power savings 1 - Clocks are not gated on idle, power saving disabled
  [23:19] MAIN_CLKGATE_CTRL2_MAIN_CG2_1_NOGATE_RSVD_PROXY — MAIN domain spare clock gate disable. These bits should remain unchanged (written only with their default value) to maintain compatibility with future devices. 0 - Clocks are gated on idle for power savings 1 - Clocks are not gated on idle, power saving disabled
  [18] MAIN_CLKGATE_CTRL2_MAIN_SA2_CPSW_PSILSS_NOGATE_PROXY — MAIN domain SA2_UL/SPCW PSILSS clock gate disable. 0 - Clocks are gated on idle for power savings 1 - Clocks are not gated on idle, power saving disabled
  [17] MAIN_CLKGATE_CTRL2_MAIN_DMPAC_VPAC_PSILSS_NOGATE_PROXY — MAIN domain DMPAC/VPAC PSILSS clock gate disable. 0 - Clocks are gated on idle for power savings 1 - Clocks are not gated on idle, power saving disabled
  [16] MAIN_CLKGATE_CTRL2_MAIN_CSI_PSILSS_NOGATE_PROXY — MAIN domain CSI PSILSS clock gate disable. 0 - Clocks are gated on idle for power savings 1 - Clocks are not gated on idle, power saving disabled
  [15:3] MAIN_CLKGATE_CTRL2_MAIN_CG2_0_NOGATE_RSVD_PROXY — MAIN domain spare clock gate disable. These bits should remain unchanged (written only with their default value) to maintain compatibility with future devices. 0 - Clocks are gated on idle for power savings 1 - Clocks are not gated on idle, power saving disabled
  [2] MAIN_CLKGATE_CTRL2_MAIN_AC_ECC_AGG_STOG_NOGATE_PROXY — MAIN domain ac ECC aggregator Slave Timeout Gasket (main_ac_ecc_aggr_stog) clock gate disable. 0 - Clocks are gated on idle for power savings 1 - Clocks are not gated on idle, power saving disabled
  [1] MAIN_CLKGATE_CTRL2_MAIN_GPU_SLV_STOG_M2P_NOGATE_PROXY — MAIN domain GPU Slave Timeout Gasket output (main_gpu_slv_stog_m2p_pwr_dis) clock gate disable. 0 - Clocks are gated on idle for power savings 1 - Clocks are not gated on idle, power saving disabled
  [0] MAIN_CLKGATE_CTRL2_MAIN_GPU_SLV_STOG_P2M_NOGATE_PROXY — MAIN domain GPU Slave Timeout Gasket input (main_gpu_slv_stog_p2m_pwr_dis) clock gate disable. 0 - Clocks are gated on idle for power savings 1 - Clocks are not gated on idle, power saving disabled
0x1A294 CFG0_MAIN_CLKGATE_CTRL3_PROXY
  [31:0] MAIN_CLKGATE_CTRL3_MAIN_CG3_NOGATE_RSVD_PROXY — MAIN domain spare clock gate disable. These bits should remain unchanged (written only with their default value) to maintain compatibility with future devices. 0 - Clocks are gated on idle for power savings 1 - Clocks are not gated on idle, power saving disabled
0x1A300 CFG0_HYPERNET_WAKE_CTRL_PROXY
  [31:1] HYPERNET_WAKE_CTRL_MW_PROXY — HYPERNET IO magic word. This 31-bit value that enables placing of the HYPERNET I/Os into isolation for daisy-chain wakeup operation. 0x5555 - Magic word value to enable isolation when qualified with mw_load bit Others - Any other value will prevent isolation when mw_load transitions from 0 to 1.
  [0] HYPERNET_WAKE_CTRL_MW_LOAD_EN_PROXY — Magic word load enable Setting this bit to 1 loads and locks the mw field for HYPERNET IO isolation. If the mw field matches the magic word value then the value is latched into the HYPERNET IO voltage domain and HYPERNET IO isolation is enabled. 0 - Unlock and do not load mw value for comparison 1 - Load and lock mw for magic word value comparison
0x1A308 CFG0_HYPERNET_WAKE_STAT0_PROXY ro
  [31:1] HYPERNET_WAKE_STAT0_MW_STAT_PROXY — HYPERNET magic word status Indicates the latched value of the mw field.
  [0] HYPERNET_WAKE_STAT0_MW_LOAD_STAT_PROXY — Magic word load status. Indicates the latched value of the mw_load_en bit
0x1A30C CFG0_HYPERNET_WAKE_STAT1_PROXY ro
  [0] HYPERNET_WAKE_STAT1_HYPERNET_IO_MODE_PROXY — Indicates if HYPERNET IO wakeup mode is enabled. 0 - Not enabled (load_en not set or mw doesn't match magic word) 1 - HYPERNET IO mode enabled
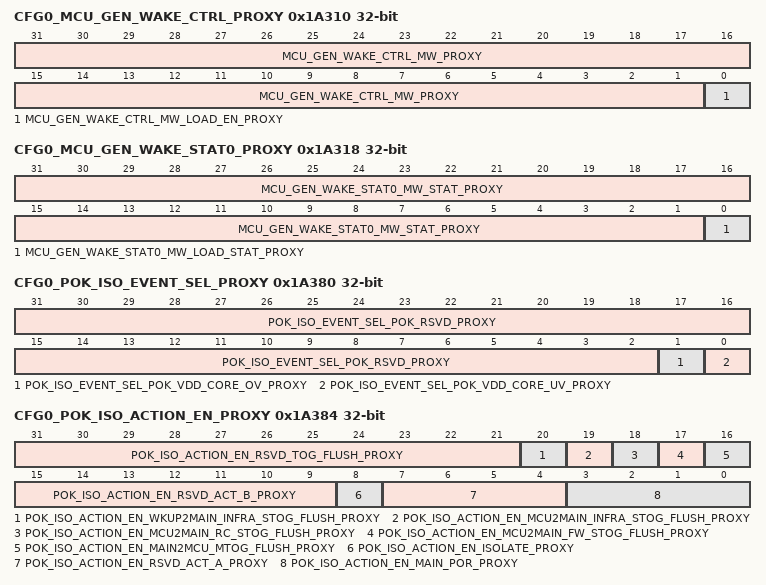
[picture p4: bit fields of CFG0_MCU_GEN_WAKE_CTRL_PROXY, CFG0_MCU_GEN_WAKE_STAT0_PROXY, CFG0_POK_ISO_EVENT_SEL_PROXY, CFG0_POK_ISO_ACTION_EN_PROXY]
0x1A310 CFG0_MCU_GEN_WAKE_CTRL_PROXY
  [31:1] MCU_GEN_WAKE_CTRL_MW_PROXY — MCU_GENERAL IO magic word. This 31-bit value that enables placing of the MCU_GENERAL I/Os into isolation for daisy-chain wakeup operation. 0x5555 - Magic word value to enable isolation when qualified with mw_load bit Others - Any other value will prevent isolation when mw_load transitions from 0 to 1.
  [0] MCU_GEN_WAKE_CTRL_MW_LOAD_EN_PROXY — Magic word load enable Setting this bit to 1 loads and locks the mw field for MCU_GENERAL IO isolation. If the mw field matches the magic word value then the value is latched into the MCU_GENERAL IO voltage domain and MCU_GENERAL IO isolation is enabled. 0 - Unlock and do not load mw value for comparison 1 - Load and lock mw for magic word value comparison
0x1A318 CFG0_MCU_GEN_WAKE_STAT0_PROXY ro
  [31:1] MCU_GEN_WAKE_STAT0_MW_STAT_PROXY — MCU_GENERAL magic word status Indicates the latched value of the mw field.
  [0] MCU_GEN_WAKE_STAT0_MW_LOAD_STAT_PROXY — Magic word load status. Indicates the latched value of the mw_load_en bit
0x1A31C CFG0_MCU_GEN_WAKE_STAT1_PROXY ro
  [0] MCU_GEN_WAKE_STAT1_MCU_GEN_IO_MODE_PROXY — Indicates if MCU_GENERAL IO wakeup mode is enabled. 0 - Not enabled (load_en not set or mw doesn't match magic word) 1 - MCU_GENERAL IO mode enabled
0x1A380 CFG0_POK_ISO_EVENT_SEL_PROXY
  [31:2] POK_ISO_EVENT_SEL_POK_RSVD_PROXY — Reserved for future use (do not optimize out)
  [1] POK_ISO_EVENT_SEL_POK_VDD_CORE_OV_PROXY — VDD_CORE overvoltage detection triggers enabled isolation actions
  [0] POK_ISO_EVENT_SEL_POK_VDD_CORE_UV_PROXY — VDD_CORE undervoltage detection triggers enabled isolation actions
0x1A384 CFG0_POK_ISO_ACTION_EN_PROXY
  [31:21] POK_ISO_ACTION_EN_RSVD_TOG_FLUSH_PROXY — Reserved timeout gasket flush enable bits. Do not optimize out 0 - Enabled POK events have no effect on this gasket 1 - Enabled POK events will assert the flush for this gasket
  [20] POK_ISO_ACTION_EN_WKUP2MAIN_INFRA_STOG_FLUSH_PROXY — WKUP to Main INFRA slave timeout gasket flush enable: 0 - Enabled POK events have no effect on this gasket 1 - Enabled POK events will assert the flush for this gasket
  [19] POK_ISO_ACTION_EN_MCU2MAIN_INFRA_STOG_FLUSH_PROXY — MCU to Main INFRA slave timeout gasket flush enable: 0 - Enabled POK events have no effect on this gasket 1 - Enabled POK events will assert the flush for this gasket
  [18] POK_ISO_ACTION_EN_MCU2MAIN_RC_STOG_FLUSH_PROXY — MCU to Main RC slave timeout gasket flush enable: 0 - Enabled POK events have no effect on this gasket 1 - Enabled POK events will assert the flush for this gasket
  [17] POK_ISO_ACTION_EN_MCU2MAIN_FW_STOG_FLUSH_PROXY — MCU to Main FW slave timeout gasket flush enable: 0 - Enabled POK events have no effect on this gasket 1 - Enabled POK events will assert the flush for this gasket
  [16] POK_ISO_ACTION_EN_MAIN2MCU_MTOG_FLUSH_PROXY — MAIN to MCU master timeout gasket flush enable: 0 - Enabled POK events have no effect on this gasket 1 - Enabled POK events will assert the flush for this gasket
  [15:9] POK_ISO_ACTION_EN_RSVD_ACT_B_PROXY — Reserved isolation action enable bits. Do not optimize out
  [8] POK_ISO_ACTION_EN_ISOLATE_PROXY — If enabled, the isolate signal will be asserted after all enabled flush signals have been asserted for 4 of their respective time-out gasket clocks when any selected POK event occurs. 0 - Isolation is not asserted on selected POK event 1 - Isolation signal is asserted on selected POK event after enabled TOG flush
  [7:4] POK_ISO_ACTION_EN_RSVD_ACT_A_PROXY — Reserved isolation action enable bits. Do not optimize out
  [3:0] POK_ISO_ACTION_EN_MAIN_POR_PROXY — When set to 4'b0110, MAIN_PORz reset is asserted when any selected POK event occurs. (Reserved for future use, do not optimize out)
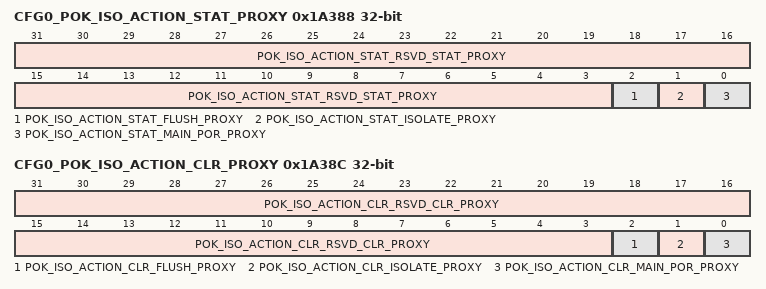
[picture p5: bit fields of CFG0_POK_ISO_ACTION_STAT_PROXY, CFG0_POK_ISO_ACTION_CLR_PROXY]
0x1A388 CFG0_POK_ISO_ACTION_STAT_PROXY ro
  [31:3] POK_ISO_ACTION_STAT_RSVD_STAT_PROXY — Reserved POK action status - do not optimize out
  [2] POK_ISO_ACTION_STAT_FLUSH_PROXY — POK activated timeout gasket flush status This signal will remain asserted until a 1 is written to the POK_ISO_ACTION_CLR_flush bit. 0 - No gasket flush is being asserted by enabled POK event 1 - Enabled gasket flush signals are being asserted due to an enabled POK event
  [1] POK_ISO_ACTION_STAT_ISOLATE_PROXY — POK activated Isolate status This signal will remain asserted until a 1 is written to the POK_ISO_ACTION_CLR_isolate bit. 0 - No isolate is being asserted by enabled POK event 1 - Isolate signal is being asserted due to an enabled POK event
  [0] POK_ISO_ACTION_STAT_MAIN_POR_PROXY — Reserved POK activated MAIN_PORz status - do not optimize out 0 - No MAIN_PORz is being asserted by enabled POK event 1 - MAIN_PORz is being asserted due to an enabled POK event
0x1A38C CFG0_POK_ISO_ACTION_CLR_PROXY
  [31:3] POK_ISO_ACTION_CLR_RSVD_CLR_PROXY — Reserved POK activated signal clear - do not optimize out Always read as 0. Writing 1 deasserts POK activated signal. 0 - Writing 0 has no effect. Bit always reads as 0 1 - Deassert signal. Bit will clear to 0 after write.
  [2] POK_ISO_ACTION_CLR_FLUSH_PROXY — POK activated timeout gasket flush clear Always read as 0. Writing 1 deasserts POK activated timeot gasket flush signals. 0 - Writing 0 has no effect. Bit always reads as 0 1 - Deassert gasket flush signals. Bit will clear to 0 after write.
  [1] POK_ISO_ACTION_CLR_ISOLATE_PROXY — POK activated isolate clear Always read as 0. Writing 1 deasserts POK activated isolate signal. 0 - Writing 0 has no effect. Bit always reads as 0 1 - Deassert isolate signal. Bit will clear to 0 after write.
  [0] POK_ISO_ACTION_CLR_MAIN_POR_PROXY — Reserved POK activated MAIN_PORz clear - do not optimize out Always read as 0. Writing 1 deasserts POK activated MAIN_PORz signal. 0 - Writing 0 has no effect. Bit always reads as 0 1 - Deassert MAIN_PORz. Bit will clear to 0 after write.
0x1A390 CFG0_POK_ISO_GP_CTRL_PROXY
  [31:0] POK_ISO_GP_CTRL_RSVD_CTRL_PROXY — Reserved POK isolation control bits
0x1A394 CFG0_POK_ISO_GP_STAT_PROXY ro
  [31:0] POK_ISO_GP_STAT_RSVD_STAT_PROXY — Reserved POK isolation status bits
{0x1B100+4i} CFG0_CLAIMREG_P6_R{i} (i=0..7)
  [31:0] CLAIMREG_P6_R{i} — Claim bits for Partition 6
